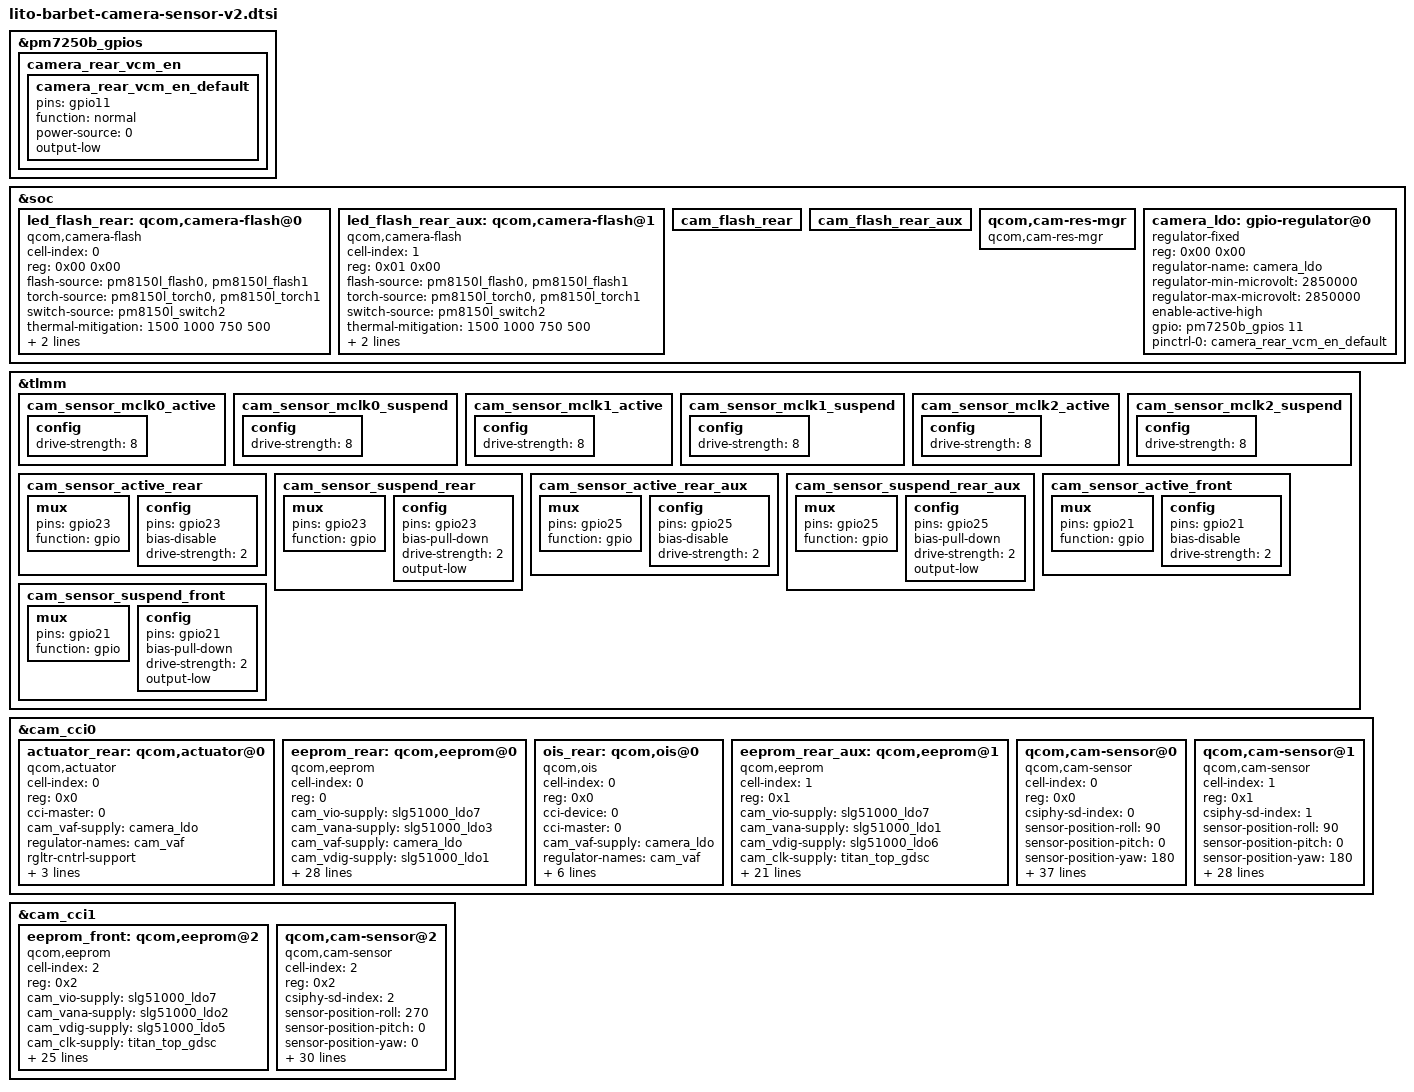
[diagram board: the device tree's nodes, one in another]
// SPDX-License-Identifier: GPL-2.0
/*
* Copyright (c) 2019, The Linux Foundation. All rights reserved.
*
* This program is free software; you can redistribute it and/or modify
* it under the terms of the GNU General Public License version 2 and
* only version 2 as published by the Free Software Foundation.
*
* This program is distributed in the hope that it will be useful,
* but WITHOUT ANY WARRANTY; without even the implied warranty of
* MERCHANTABILITY or FITNESS FOR A PARTICULAR PURPOSE.  See the
* GNU General Public License for more details.
*/
#include <dt-bindings/clock/qcom,camcc-lito.h>
#include "lito-barbet-camera-pmic.dtsi"

&pm7250b_gpios {
	camera_rear_vcm_en {
		camera_rear_vcm_en_default: camera_rear_vcm_en_default {
			pins = "gpio11";
			function = "normal";
			power-source = <0>;
			output-low;
		};
	};
};

&soc {
	led_flash_rear: qcom,camera-flash@0 {
		cell-index = <0>;
		reg = <0x00 0x00>;
		compatible = "qcom,camera-flash";
		flash-source = <&pm8150l_flash0 &pm8150l_flash1>;
		torch-source = <&pm8150l_torch0 &pm8150l_torch1>;
		switch-source = <&pm8150l_switch2>;
		thermal-mitigation = <1500 1000 750 500>;
		#cooling-cells = <2>;
		bcl-node-name = "bcl_flash_rear";
		cooling-name = "cam_flash_rear";
	};

	led_flash_rear_aux: qcom,camera-flash@1 {
		cell-index = <1>;
		reg = <0x01 0x00>;
		compatible = "qcom,camera-flash";
		flash-source = <&pm8150l_flash0 &pm8150l_flash1>;
		torch-source = <&pm8150l_torch0 &pm8150l_torch1>;
		switch-source = <&pm8150l_switch2>;
		thermal-mitigation = <1500 1000 750 500>;
		#cooling-cells = <2>;
		bcl-node-name = "bcl_flash_rear_aux";
		cooling-name = "cam_flash_rear_aux";
	};

	cam_flash_rear: cam_flash_rear {
		#cooling-cells = <2>;
	};

	cam_flash_rear_aux: cam_flash_rear_aux {
		#cooling-cells = <2>;
	};

	qcom,cam-res-mgr {
		compatible = "qcom,cam-res-mgr";
		status = "ok";
	};

	camera_ldo: gpio-regulator@0 {
		compatible = "regulator-fixed";
		reg = <0x00 0x00>;
		regulator-name = "camera_ldo";
		regulator-min-microvolt = <2850000>;
		regulator-max-microvolt = <2850000>;
		enable-active-high;
		gpio = <&pm7250b_gpios 11 GPIO_ACTIVE_HIGH>;
		pinctrl-names = "default";
		pinctrl-0 = <&camera_rear_vcm_en_default>;
	};
};

&tlmm {
	cam_sensor_mclk0_active: cam_sensor_mclk0_active {
		/* MCLK0 */
		config {
			drive-strength = <8>; /* 8 MA */
		};
	};

	cam_sensor_mclk0_suspend: cam_sensor_mclk0_suspend {
		/* MCLK0 */
		config {
			drive-strength = <8>; /* 8 MA */
		};
	};

	cam_sensor_mclk1_active: cam_sensor_mclk1_active {
		/* MCLK1 */
		config {
			drive-strength = <8>; /* 8 MA */
		};
	};

	cam_sensor_mclk1_suspend: cam_sensor_mclk1_suspend {
		/* MCLK1 */
		config {
			drive-strength = <8>; /* 8 MA */
		};
	};

	cam_sensor_mclk2_active: cam_sensor_mclk2_active {
		/* MCLK2 */
		config {
			drive-strength = <8>; /* 8 MA */
		};
	};

	cam_sensor_mclk2_suspend: cam_sensor_mclk2_suspend {
		/* MCLK2 */
		config {
			drive-strength = <8>; /* 8 MA */
		};
	};

	cam_sensor_active_rear: cam_sensor_active_rear {
		/* RESET REAR2 */
		mux {
			pins = "gpio23";
			function = "gpio";
		};

		config {
			pins = "gpio23";
			bias-disable; /* No PULL */
			drive-strength = <2>; /* 2 MA */
		};
	};

	cam_sensor_suspend_rear: cam_sensor_suspend_rear {
		/* RESET REAR2 */
		mux {
			pins = "gpio23";
			function = "gpio";
		};

		config {
			pins = "gpio23";
			bias-pull-down; /* PULL DOWN */
			drive-strength = <2>; /* 2 MA */
			output-low;
		};
	};

	cam_sensor_active_rear_aux: cam_sensor_active_rear_aux {
		/* RESET REARAUX,DVDD ELDO */
		mux {
			pins = "gpio25";
			function = "gpio";
		};

		config {
			pins = "gpio25";
			bias-disable; /* No PULL */
			drive-strength = <2>; /* 2 MA */
		};
	};

	cam_sensor_suspend_rear_aux: cam_sensor_suspend_rear_aux {
		/* RESET REARAUX,DVDD ELDO */
		mux {
			pins = "gpio25";
			function = "gpio";
		};

		config {
			pins = "gpio25";
			bias-pull-down; /* PULL DOWN */
			drive-strength = <2>; /* 2 MA */
			output-low;
		};
	};

	cam_sensor_active_front: cam_sensor_active_front {
		/* RESET FRONT */
		mux {
			pins = "gpio21";
			function = "gpio";
		};

		config {
			pins = "gpio21";
			bias-disable; /* No PULL */
			drive-strength = <2>; /* 2 MA */
		};
	};

	cam_sensor_suspend_front: cam_sensor_suspend_front {
		/* RESET FRONT */
		mux {
			pins = "gpio21";
			function = "gpio";
		};

		config {
			pins = "gpio21";
			bias-pull-down; /* PULL DOWN */
			drive-strength = <2>; /* 2 MA */
			output-low;
		};
	};
};

&cam_cci0 {

	actuator_rear: qcom,actuator@0 {
		cell-index = <0>;
		reg = <0x0>;
		compatible = "qcom,actuator";
		cci-master = <0>;
		cam_vaf-supply = <&camera_ldo>;
		regulator-names = "cam_vaf";
		rgltr-cntrl-support;
		rgltr-min-voltage = <2850000>;
		rgltr-max-voltage = <2850000>;
		rgltr-load-current = <80000>;
		status = "ok";
	};

	eeprom_rear: qcom,eeprom@0 {
		cell-index = <0>;
		reg = <0>;
		compatible = "qcom,eeprom";
		cam_vio-supply = <&slg51000_ldo7>;
		cam_vana-supply = <&slg51000_ldo3>;
		cam_vaf-supply = <&camera_ldo>;
		cam_vdig-supply = <&slg51000_ldo1>;
		cam_v_custom1-supply = <&slg51000_ldo4>;
		cam_v_custom2-supply = <&slg51000_ldo6>;
		cam_clk-supply = <&titan_top_gdsc>;
		regulator-names = "cam_vio", "cam_vana", "cam_vaf", "cam_vdig",
			"cam_v_custom1", "cam_v_custom2", "cam_clk";
		rgltr-cntrl-support;
		rgltr-min-voltage = <1800000 2850000 2850000 2850000 1800000
			1100000 0>;
		rgltr-max-voltage = <1800000 2850000 2850000 2850000 1800000
			1100000 0>;
		rgltr-load-current = <0 0 8000 0 0 0 0>;
		gpio-no-mux = <0>;
		pinctrl-names = "cam_default", "cam_suspend";
		pinctrl-0 = <&cam_sensor_mclk0_active
				&cam_sensor_active_rear>;
		pinctrl-1 = <&cam_sensor_mclk0_suspend
				&cam_sensor_suspend_rear>;
		gpios = <&tlmm 13 0>,
			<&tlmm 23 0>;
		gpio-reset = <1>;
		gpio-req-tbl-num = <0 1>;
		gpio-req-tbl-flags = <1 0>;
		gpio-req-tbl-label = "CAMIF_MCLK0",
					"CAM_RESET0";
		sensor-position = <0>;
		sensor-mode = <0>;
		cci-master = <0>;
		status = "ok";
		clocks = <&camcc CAM_CC_MCLK0_CLK>;
		clock-names = "cam_clk";
		clock-cntl-level = "turbo";
		clock-rates = <24000000>;
	};

	ois_rear: qcom,ois@0 {
		cell-index = <0>;
		reg = <0x0>;
		compatible = "qcom,ois";
		cci-device = <0>;
		cci-master = <0>;
		cam_vaf-supply = <&camera_ldo>;
		regulator-names = "cam_vaf";
		rgltr-cntrl-support;
		rgltr-min-voltage = <2850000>;
		rgltr-max-voltage = <2850000>;
		rgltr-load-current = <80000>;
		gyro-correct-enable = <0>;
		gyro-correct-index = <0>;
	};

	eeprom_rear_aux: qcom,eeprom@1 {
		cell-index = <1>;
		reg = <0x1>;
		compatible = "qcom,eeprom";
		cam_vio-supply = <&slg51000_ldo7>;
		cam_vana-supply = <&slg51000_ldo1>;
		cam_vdig-supply = <&slg51000_ldo6>;
		cam_clk-supply = <&titan_top_gdsc>;
		regulator-names = "cam_vio", "cam_vana", "cam_vdig", "cam_clk";
		rgltr-cntrl-support;
		rgltr-min-voltage = <1800000 2850000 1100000 0>;
		rgltr-max-voltage = <1800000 2850000 1100000 0>;
		rgltr-load-current = <0 0 0 0>;
		gpio-no-mux = <0>;
		pinctrl-names = "cam_default", "cam_suspend";
		pinctrl-0 = <&cam_sensor_mclk1_active
			&cam_sensor_active_rear_aux>;
		pinctrl-1 = <&cam_sensor_mclk1_suspend
			&cam_sensor_suspend_rear_aux>;
		gpios = <&tlmm 14 0>,
			<&tlmm 25 0>;
		gpio-reset = <1>;
		gpio-req-tbl-num = <0 1>;
		gpio-req-tbl-flags = <1 0>;
		gpio-req-tbl-label = "CAMIF_MCLK1",
			"CAM_RESET1";
		sensor-mode = <0>;
		cci-master = <1>;
		clocks = <&camcc CAM_CC_MCLK1_CLK>;
		clock-names = "cam_clk";
		clock-cntl-level = "turbo";
		clock-rates = <24000000>;
		status="ok";
	};

	qcom,cam-sensor@0 {
		cell-index = <0>;
		compatible = "qcom,cam-sensor";
		reg = <0x0>;
		csiphy-sd-index = <0>;
		sensor-position-roll = <90>;
		sensor-position-pitch = <0>;
		sensor-position-yaw = <180>;
		led-flash-src = <&led_flash_rear>;
		actuator-src = <&actuator_rear>;
		eeprom-src = <&eeprom_rear>;
		ois-src = <&ois_rear>;
		cam_vio-supply = <&slg51000_ldo7>;
		cam_vana-supply = <&slg51000_ldo3>;
		cam_vaf-supply = <&camera_ldo>;
		cam_vdig-supply = <&slg51000_ldo1>;
		cam_v_custom1-supply = <&slg51000_ldo4>;
		cam_v_custom2-supply = <&slg51000_ldo6>;
		cam_clk-supply = <&titan_top_gdsc>;
		regulator-names = "cam_vio", "cam_vana", "cam_vaf", "cam_vdig",
			"cam_v_custom1", "cam_v_custom2", "cam_clk";
		rgltr-cntrl-support;
		pwm-switch;
		rgltr-min-voltage = <1800000 2850000 2850000 2850000 1800000
			1100000 0>;
		rgltr-max-voltage = <1800000 2850000 2850000 2850000 1800000
			1100000 0>;
		rgltr-load-current = <0 0 8000 0 0 0 0>;
		gpio-no-mux = <0>;
		pinctrl-names = "cam_default", "cam_suspend";
		pinctrl-0 = <&cam_sensor_mclk0_active
			&cam_sensor_active_rear>;
		pinctrl-1 = <&cam_sensor_mclk0_suspend
			&cam_sensor_suspend_rear>;
		gpios = <&tlmm 13 0>,
			<&tlmm 23 0>;
		gpio-reset = <1>;
		gpio-req-tbl-num = <0 1>;
		gpio-req-tbl-flags = <1 0>;
		gpio-req-tbl-label = "CAMIF_MCLK0",
			"CAM_RESET0";
		sensor-mode = <0>;
		cci-master = <0>;
		cci-device = <0>;
		status = "ok";
		clocks = <&camcc CAM_CC_MCLK0_CLK>;
		clock-names = "cam_clk";
		clock-cntl-level = "turbo";
		clock-rates = <24000000>;
	};

	qcom,cam-sensor@1 {
		cell-index = <1>;
		compatible = "qcom,cam-sensor";
		reg = <0x1>;
		csiphy-sd-index = <1>;
		sensor-position-roll = <90>;
		sensor-position-pitch = <0>;
		sensor-position-yaw = <180>;
		led-flash-src = <&led_flash_rear_aux>;
		eeprom-src = <&eeprom_rear_aux>;
		cam_vio-supply = <&slg51000_ldo7>;
		cam_vana-supply = <&slg51000_ldo1>;
		cam_vdig-supply = <&slg51000_ldo6>;
		cam_clk-supply = <&titan_top_gdsc>;
		regulator-names = "cam_vio", "cam_vana", "cam_vdig", "cam_clk";
		rgltr-cntrl-support;
		pwm-switch;
		rgltr-min-voltage = <1800000 2850000 1100000 0>;
		rgltr-max-voltage = <1800000 2850000 1100000 0>;
		rgltr-load-current = <0 0 0 0>;
		gpio-no-mux = <0>;
		pinctrl-names = "cam_default", "cam_suspend";
		pinctrl-0 = <&cam_sensor_mclk1_active
			&cam_sensor_active_rear_aux>;
		pinctrl-1 = <&cam_sensor_mclk1_suspend
			&cam_sensor_suspend_rear_aux>;
		gpios = <&tlmm 14 0>,
			<&tlmm 25 0>;
		gpio-reset = <1>;
		gpio-req-tbl-num = <0 1>;
		gpio-req-tbl-flags = <1 0>;
		gpio-req-tbl-label = "CAMIF_MCLK1",
			"CAM_RESET1";
		sensor-mode = <0>;
		cci-master = <1>;
		clocks = <&camcc CAM_CC_MCLK1_CLK>;
		clock-names = "cam_clk";
		clock-cntl-level = "turbo";
		status = "ok";
		clock-rates = <24000000>;
	};
};

&cam_cci1 {
	eeprom_front: qcom,eeprom@2 {
		cell-index = <2>;
		reg = <0x2>;
		compatible = "qcom,eeprom";
		cam_vio-supply = <&slg51000_ldo7>;
		cam_vana-supply = <&slg51000_ldo2>;
		cam_vdig-supply = <&slg51000_ldo5>;
		cam_clk-supply = <&titan_top_gdsc>;
		regulator-names = "cam_vio", "cam_vana", "cam_vdig", "cam_clk";
		rgltr-cntrl-support;
		rgltr-min-voltage = <1800000 2850000 1100000 0>;
		rgltr-max-voltage = <1800000 2850000 1100000 0>;
		rgltr-load-current = <0 0 0 0>;
		gpio-no-mux = <0>;
		pinctrl-names = "cam_default", "cam_suspend";
		pinctrl-0 = <&cam_sensor_mclk2_active
			&cam_sensor_active_front>;
		pinctrl-1 = <&cam_sensor_mclk2_suspend
			&cam_sensor_suspend_front>;
		gpios = <&tlmm 15 0>,
			<&tlmm 21 0>,
			<&pm8150l_gpios 2 0>;
		gpio-reset = <1>;
		gpio-custom1 = <2>;
		gpio-req-tbl-num = <0 1 2>;
		gpio-req-tbl-flags = <1 0 0>;
		gpio-req-tbl-label = "CAMIF_MCLK2",
			"CAM_RESET2",
			"CUSTOM_GPIO1";
		sensor-position = <1>;
		sensor-mode = <0>;
		cci-device = <1>;
		cci-master = <0>;
		status = "ok";
		clocks = <&camcc CAM_CC_MCLK2_CLK>;
		clock-names = "cam_clk";
		clock-cntl-level = "turbo";
		clock-rates = <24000000>;
	};

	qcom,cam-sensor@2 {
		cell-index = <2>;
		compatible = "qcom,cam-sensor";
		reg = <0x2>;
		csiphy-sd-index = <2>;
		sensor-position-roll = <270>;
		sensor-position-pitch = <0>;
		sensor-position-yaw = <0>;
		eeprom-src = <&eeprom_front>;
		cam_vio-supply = <&slg51000_ldo7>;
		cam_vana-supply = <&slg51000_ldo2>;
		cam_vdig-supply = <&slg51000_ldo5>;
		cam_clk-supply = <&titan_top_gdsc>;
		regulator-names = "cam_vio", "cam_vana", "cam_vdig", "cam_clk";
		rgltr-cntrl-support;
		pwm-switch;
		rgltr-min-voltage = <1800000 2800000 1200000 0>;
		rgltr-max-voltage = <1800000 2800000 1200000 0>;
		rgltr-load-current = <0 0 0 0>;
		gpio-no-mux = <0>;
		pinctrl-names = "cam_default", "cam_suspend";
		pinctrl-0 = <&cam_sensor_mclk2_active
			 &cam_sensor_active_front>;
		pinctrl-1 = <&cam_sensor_mclk2_suspend
			 &cam_sensor_suspend_front>;
		gpios = <&tlmm 15 0>,
			<&tlmm 21 0>,
			<&pm8150l_gpios 2 0>;
		gpio-reset = <1>;
		gpio-custom1 = <2>;
		gpio-req-tbl-num = <0 1 2>;
		gpio-req-tbl-flags = <1 0 0>;
		gpio-req-tbl-label = "CAMIF_MCLK2",
			"CAM_RESET2",
			"CUSTOM_GPIO1";
		sensor-mode = <0>;
		cci-device = <1>;
		cci-master = <0>;
		status = "ok";
		clocks = <&camcc CAM_CC_MCLK2_CLK>;
		clock-names = "cam_clk";
		clock-cntl-level = "turbo";
		clock-rates = <24000000>;
	};
};
